AUTOSAR XML (schema 00049)
package /vector/adas_application
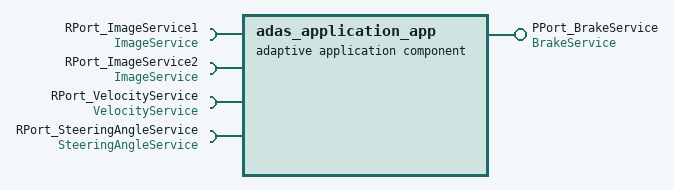
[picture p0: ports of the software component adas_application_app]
  adaptive application sw component type adas_application_app
    provide port PPort_BrakeService: provided-interface=BrakeService
    4 x require port:
      RPort_ImageService1: required-interface=ImageService
      RPort_ImageService2: required-interface=ImageService
      RPort_VelocityService: required-interface=VelocityService
      RPort_SteeringAngleService: required-interface=SteeringAngleService
  executable adas_application: category=APPLICATION_LEVEL, reporting-behavior=REPORTS-EXECUTION-STATE, version=1.0.0
    root sw component prototype rootSwc: application-type=adas_application_app
  process design adas_application_process_design: executable=adas_application
  process adas_application_process: design=adas_application_process_design, executable=adas_application, state-dependent-startup-config{function-group-state=[MachineFG.Running, MachineFG.Startup], startup-config=adas_demod_startup_config}
    process state machine adas_demo_app_processProcessStatesPrototype: type=MachineStates
  software cluster adas_application_software_cluster: category=PLATFORM_CORE, claimed-function-group=MachineFG, contained-process=adas_application_process, version=1.0.0
  startup config set adas_application_startup_config_set
    startup config adas_demod_startup_config: process-arguments=[-c, ./etc/adas_demod-posix.json], scheduling-policy=SCHED_FIFO, scheduling-priority=12
